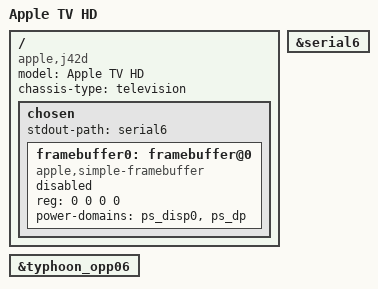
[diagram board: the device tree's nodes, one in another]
// SPDX-License-Identifier: GPL-2.0+ OR MIT
/*
 * Apple TV HD, J42d, AppleTV5,3 (A1625)
 * Copyright (c) 2022, Konrad Dybcio <konradybcio@kernel.org>
 */

/dts-v1/;

#include "t7000.dtsi"
#include "t7000-common.dtsi"

/ {
	compatible = "apple,j42d", "apple,t7000", "apple,arm-platform";
	model = "Apple TV HD";
	chassis-type = "television";

	chosen {
		stdout-path = "serial6";

		framebuffer0: framebuffer@0 {
			compatible = "apple,simple-framebuffer", "simple-framebuffer";
			reg = <0 0 0 0>; /* To be filled by loader */
			power-domains = <&ps_disp0 &ps_dp>;
			/* Format properties will be added by loader */
			status = "disabled";
		};
	};
};

&serial6 {
	status = "okay";
};

&typhoon_opp06 {
	status = "okay";
};
